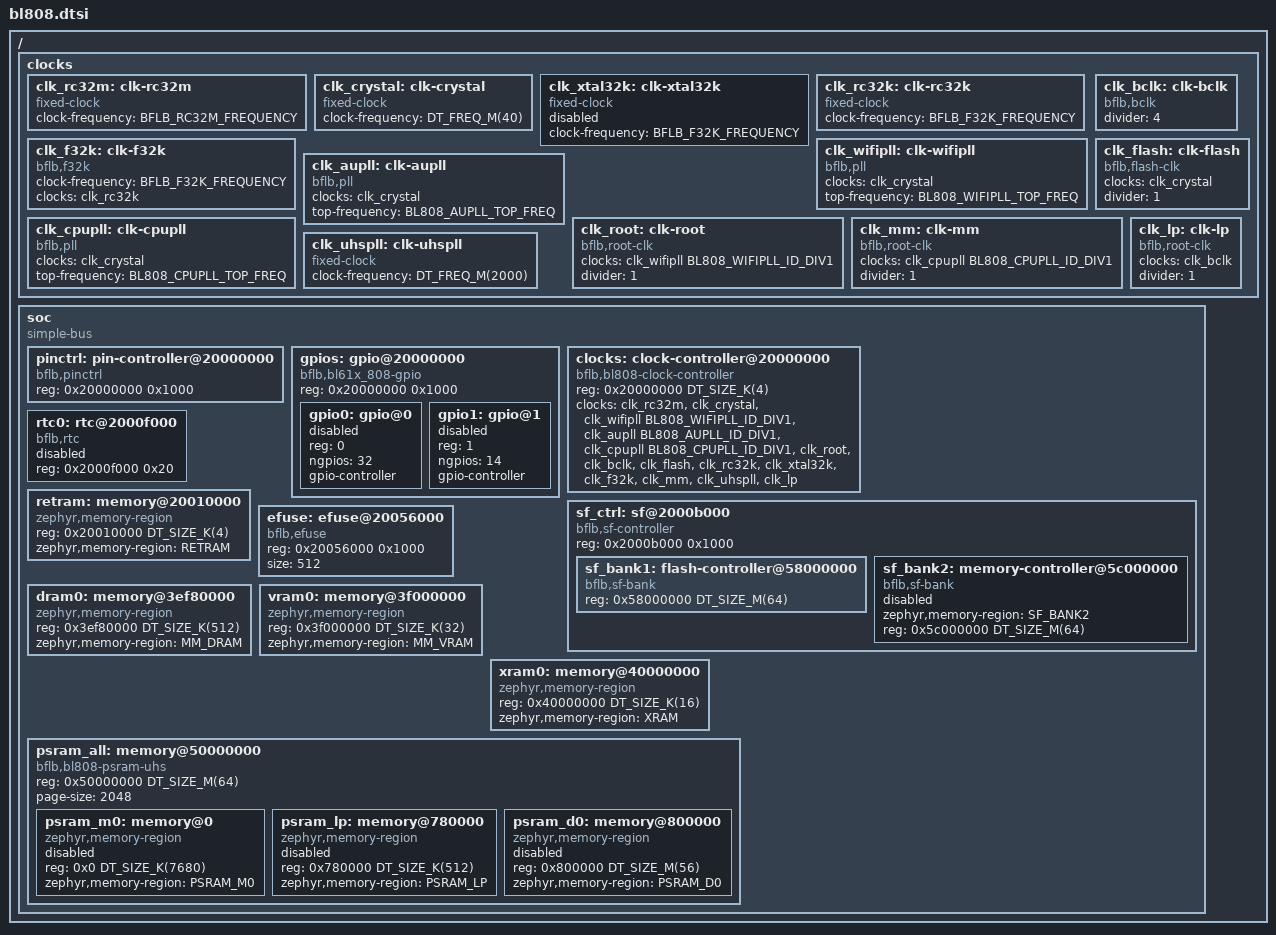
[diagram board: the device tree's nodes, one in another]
/*
 * Copyright The Zephyr Project Contributors
 *
 * SPDX-License-Identifier: Apache-2.0
 */

#include <freq.h>
#include <mem.h>
#include <zephyr/dt-bindings/clock/bflb_bl808_clock.h>
#include <zephyr/dt-bindings/i2c/i2c.h>
#include <zephyr/dt-bindings/pinctrl/bflb-common-pinctrl.h>
#include <zephyr/dt-bindings/pinctrl/bl808x-pinctrl.h>
#include <zephyr/dt-bindings/gpio/gpio.h>

/ {
	#address-cells = <1>;
	#size-cells = <1>;

	clocks {
		clk_rc32m: clk-rc32m {
			#clock-cells = <0>;
			compatible = "fixed-clock";
			clock-frequency = <BFLB_RC32M_FREQUENCY>;
			status = "okay";
		};

		clk_crystal: clk-crystal {
			#clock-cells = <0>;
			compatible = "fixed-clock";
			clock-frequency = <DT_FREQ_M(40)>;
			status = "okay";
		};

		clk_xtal32k: clk-xtal32k {
			#clock-cells = <0>;
			compatible = "fixed-clock";
			clock-frequency = <BFLB_F32K_FREQUENCY>;
			status = "disabled";
		};

		clk_rc32k: clk-rc32k {
			#clock-cells = <0>;
			compatible = "fixed-clock";
			clock-frequency = <BFLB_F32K_FREQUENCY>;
			status = "okay";
		};

		clk_f32k: clk-f32k {
			#clock-cells = <0>;
			compatible = "bflb,f32k";
			clock-frequency = <BFLB_F32K_FREQUENCY>;
			clocks = <&clk_rc32k>;
			status = "okay";
		};

		clk_wifipll: clk-wifipll {
			#clock-cells = <1>;
			compatible = "bflb,pll";
			clocks = <&clk_crystal>;
			top-frequency = <BL808_WIFIPLL_TOP_FREQ>;
			status = "okay";
		};

		clk_aupll: clk-aupll {
			#clock-cells = <1>;
			compatible = "bflb,pll";
			clocks = <&clk_crystal>;
			top-frequency = <BL808_AUPLL_TOP_FREQ>;
			status = "okay";
		};

		clk_cpupll: clk-cpupll {
			#clock-cells = <1>;
			compatible = "bflb,pll";
			clocks = <&clk_crystal>;
			top-frequency = <BL808_CPUPLL_TOP_FREQ>;
			status = "okay";
		};

		clk_root: clk-root {
			#clock-cells = <0>;
			compatible = "bflb,root-clk";
			clocks = <&clk_wifipll BL808_WIFIPLL_ID_DIV1>;
			divider = <1>;
			status = "okay";
		};

		clk_bclk: clk-bclk {
			#clock-cells = <0>;
			compatible = "bflb,bclk";
			divider = <4>;
			status = "okay";
		};

		clk_flash: clk-flash {
			#clock-cells = <0>;
			compatible = "bflb,flash-clk";
			clocks = <&clk_crystal>;
			divider = <1>;
			status = "okay";
		};

		clk_mm: clk-mm {
			#clock-cells = <0>;
			compatible = "bflb,root-clk";
			clocks = <&clk_cpupll BL808_CPUPLL_ID_DIV1>;
			divider = <1>;
			status = "okay";
		};

		clk_uhspll: clk-uhspll {
			#clock-cells = <0>;
			compatible = "fixed-clock";
			clock-frequency = <DT_FREQ_M(2000)>;
			status = "okay";
		};

		clk_lp: clk-lp {
			#clock-cells = <0>;
			compatible = "bflb,root-clk";
			clocks = <&clk_bclk>;
			divider = <1>;
			status = "okay";
		};
	};

	soc {
		compatible = "simple-bus";
		#address-cells = <1>;
		#size-cells = <1>;
		ranges;

		pinctrl: pin-controller@20000000 {
			compatible = "bflb,pinctrl";
			reg = <0x20000000 0x1000>;
			#address-cells = <1>;
			#size-cells = <1>;
			ranges;
			status = "okay";
		};

		gpios: gpio@20000000 {
			compatible = "bflb,bl61x_808-gpio";
			reg = <0x20000000 0x1000>;
			#address-cells = <1>;
			#size-cells = <0>;

			gpio0: gpio@0 {
				#gpio-cells = <2>;
				reg = <0>;
				ngpios = <32>;
				status = "disabled";
				gpio-controller;
			};

			gpio1: gpio@1 {
				#gpio-cells = <2>;
				reg = <1>;
				ngpios = <14>;
				status = "disabled";
				gpio-controller;
			};
		};

		clocks: clock-controller@20000000 {
			compatible = "bflb,bl808-clock-controller", "bflb,clock-controller";
			reg = <0x20000000 DT_SIZE_K(4)>;
			#clock-cells = <1>;
			status = "okay";
			clocks = <&clk_rc32m>, <&clk_crystal>,
				 <&clk_wifipll BL808_WIFIPLL_ID_DIV1>,
				 <&clk_aupll BL808_AUPLL_ID_DIV1>,
				 <&clk_cpupll BL808_CPUPLL_ID_DIV1>,
				 <&clk_root>, <&clk_bclk>, <&clk_flash>,
				 <&clk_rc32k>, <&clk_xtal32k>, <&clk_f32k>,
				 <&clk_mm>, <&clk_uhspll>, <&clk_lp>;
			clock-names = "rc32m", "crystal",
				      "wifipll_top",
				      "aupll_top",
				      "cpupll_top",
				      "root", "bclk", "flash",
				      "rc32k", "xtal32k", "f32k",
				      "mm", "uhspll_top", "lp";
		};

		sf_ctrl: sf@2000b000 {
			compatible = "bflb,sf-controller";
			reg = <0x2000b000 0x1000>;
			ranges;
			#address-cells = <1>;
			#size-cells = <1>;

			sf_bank1: flash-controller@58000000 {
				compatible = "bflb,sf-bank";
				reg = <0x58000000 DT_SIZE_M(64)>;
				ranges = <0x0 0x58000000 DT_SIZE_M(64)>;
				#address-cells = <1>;
				#size-cells = <1>;
			};

			sf_bank2: memory-controller@5c000000 {
				/* Only have the memory-region compatible
				 * when not using a pre-existing (ROM) memory region
				 */
				compatible = "bflb,sf-bank", "zephyr,memory-region";
				zephyr,memory-region = "SF_BANK2";
				reg = <0x5c000000 DT_SIZE_M(64)>;
				ranges = <0x0 0x5c000000 DT_SIZE_M(64)>;
				#address-cells = <1>;
				#size-cells = <1>;
				status = "disabled";
			};
		};

		rtc0: rtc@2000f000 {
			compatible = "bflb,rtc";
			reg = <0x2000f000 0x20>;
			status = "disabled";
		};

		retram: memory@20010000 {
			compatible = "zephyr,memory-region", "mmio-sram";
			reg = <0x20010000 DT_SIZE_K(4)>;
			#address-cells = <1>;
			#size-cells = <1>;
			ranges = <0x0 0x20010000 DT_SIZE_K(4)>;
			zephyr,memory-region = "RETRAM";
		};

		efuse: efuse@20056000 {
			compatible = "bflb,efuse";
			reg = <0x20056000 0x1000>;
			status = "okay";
			size = <512>;
		};

		/* DRAM is reserved as D0's main RAM */
		dram0: memory@3ef80000 {
			compatible = "zephyr,memory-region", "mmio-sram";
			reg = <0x3ef80000 DT_SIZE_K(512)>;
			#address-cells = <1>;
			#size-cells = <1>;
			ranges = <0x0 0x3ef80000 DT_SIZE_K(512)>;
			zephyr,memory-region = "MM_DRAM";
		};

		vram0: memory@3f000000 {
			compatible = "zephyr,memory-region", "mmio-sram";
			reg = <0x3f000000 DT_SIZE_K(32)>;
			#address-cells = <1>;
			#size-cells = <1>;
			ranges = <0x0 0x3f000000 DT_SIZE_K(32)>;
			zephyr,memory-region = "MM_VRAM";
		};

		xram0: memory@40000000 {
			compatible = "zephyr,memory-region", "mmio-sram";
			reg = <0x40000000 DT_SIZE_K(16)>;
			#address-cells = <1>;
			#size-cells = <1>;
			ranges = <0x0 0x40000000 DT_SIZE_K(16)>;
			zephyr,memory-region = "XRAM";
		};

		/* Define 'psram' reserved memory regions per-CPU.
		 * it is initialized by M0 before starting the other CPUs
		 * so only M0 has to care about not using it too early
		 */
		psram_all: memory@50000000 {
			compatible = "bflb,bl808-psram-uhs";
			reg = <0x50000000 DT_SIZE_M(64)>;
			#address-cells = <1>;
			#size-cells = <1>;
			ranges = <0x0 0x50000000 DT_SIZE_M(64)>;
			page-size = <2048>;

			/* 7.5 MB for M0 */
			psram_m0: memory@0 {
				compatible = "zephyr,memory-region";
				reg = <0x0 DT_SIZE_K(7680)>;
				#address-cells = <1>;
				#size-cells = <1>;
				ranges = <0x0 0x0 DT_SIZE_K(7680)>;
				zephyr,memory-region = "PSRAM_M0";
				status = "disabled";
			};

			/* 512 KB for LP */
			psram_lp: memory@780000 {
				compatible = "zephyr,memory-region";
				reg = <0x780000 DT_SIZE_K(512)>;
				#address-cells = <1>;
				#size-cells = <1>;
				ranges = <0x0 0x780000 DT_SIZE_K(512)>;
				zephyr,memory-region = "PSRAM_LP";
				status = "disabled";
			};

			/* 56 MB for D0 */
			psram_d0: memory@800000 {
				compatible = "zephyr,memory-region";
				reg = <0x800000 DT_SIZE_M(56)>;
				#address-cells = <1>;
				#size-cells = <1>;
				ranges = <0x0 0x800000 DT_SIZE_M(56)>;
				zephyr,memory-region = "PSRAM_D0";
				status = "disabled";
			};
		};
	};
};
